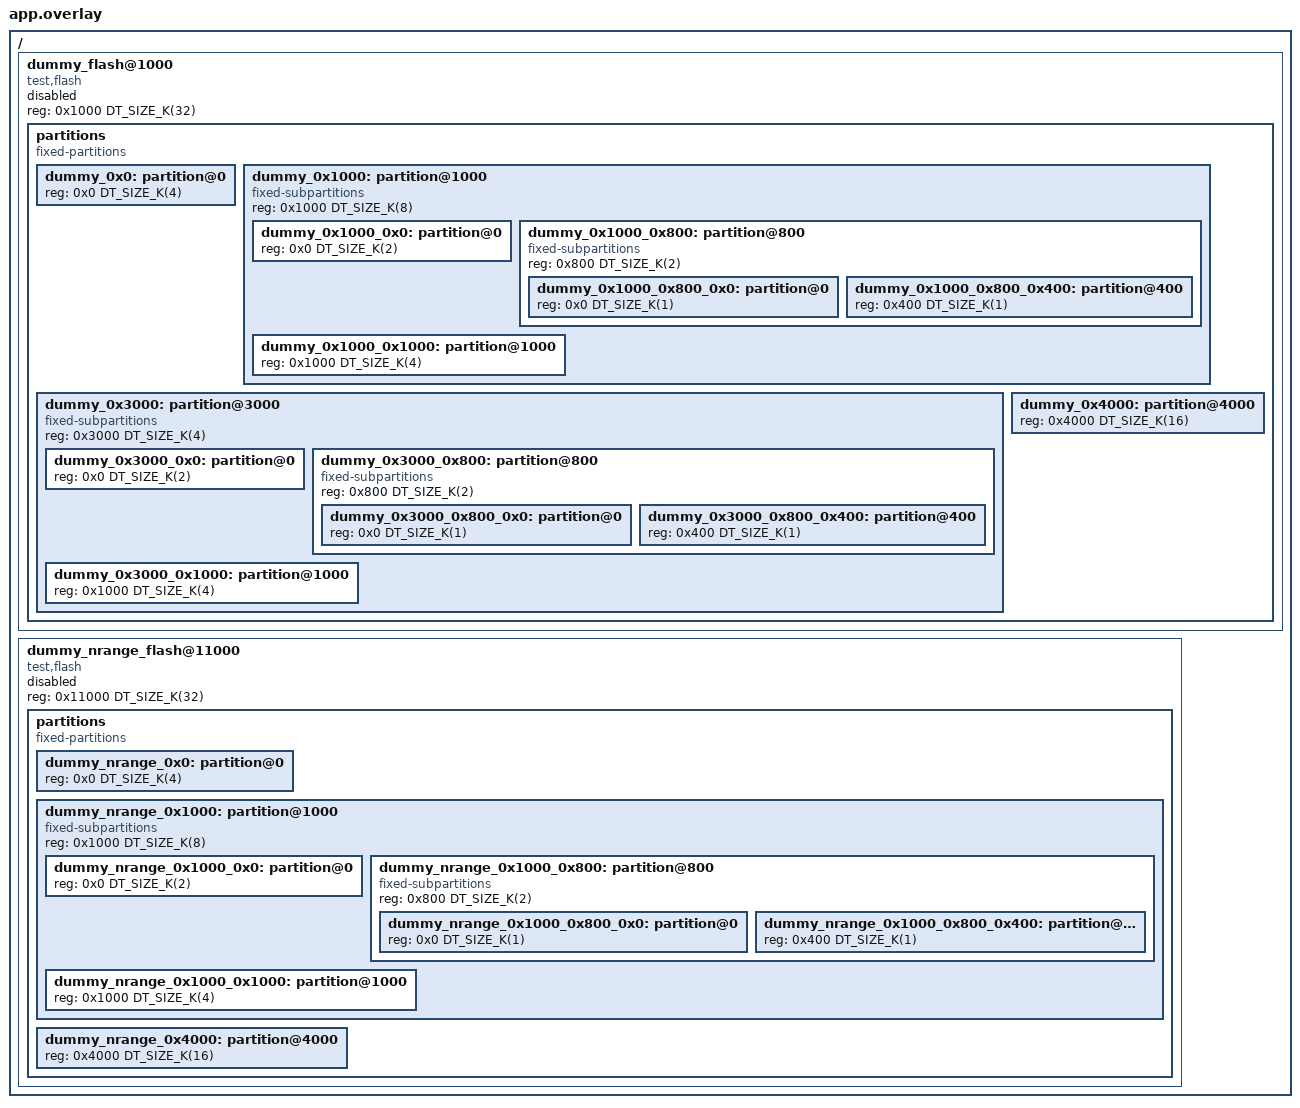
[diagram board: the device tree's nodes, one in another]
/*
 * Copyright (c) 2026 Nordic Semiconductor ASA
 *
 * SPDX-License-Identifier: LicenseRef-Nordic-5-Clause
 */

/ {
	dummy_flash@1000 {
		compatible = "test,flash";
		reg = <0x1000 DT_SIZE_K(32)>;
		ranges = <0x0 0x1000 DT_SIZE_K(32)>;
		status = "disabled";
		#address-cells = <1>;
		#size-cells = <1>;

		partitions {
			compatible = "fixed-partitions";
			ranges;
			#address-cells = <1>;
			#size-cells = <1>;

			dummy_0x0: partition@0 {
				reg = <0x0 DT_SIZE_K(4)>;
			};

			dummy_0x1000: partition@1000 {
				compatible = "fixed-subpartitions";
				reg = <0x1000 DT_SIZE_K(8)>;
				ranges = <0x0 0x1000 DT_SIZE_K(8)>;
				#address-cells = <1>;
				#size-cells = <1>;

				dummy_0x1000_0x0: partition@0 {
					reg = <0x0 DT_SIZE_K(2)>;
				};

				dummy_0x1000_0x800: partition@800 {
					compatible = "fixed-subpartitions";
					reg = <0x800 DT_SIZE_K(2)>;
					ranges = <0x0 0x800 DT_SIZE_K(2)>;
					#address-cells = <1>;
					#size-cells = <1>;

					dummy_0x1000_0x800_0x0: partition@0 {
						reg = <0x0 DT_SIZE_K(1)>;
					};

					dummy_0x1000_0x800_0x400: partition@400 {
						reg = <0x400 DT_SIZE_K(1)>;
					};
				};

				dummy_0x1000_0x1000: partition@1000 {
					reg = <0x1000 DT_SIZE_K(4)>;
				};
			};

			dummy_0x3000: partition@3000 {
				compatible = "fixed-subpartitions";
				reg = <0x3000 DT_SIZE_K(4)>;
				/* Intentionally do not define ranges. */
				#address-cells = <1>;
				#size-cells = <1>;

				dummy_0x3000_0x0: partition@0 {
					reg = <0x0 DT_SIZE_K(2)>;
				};

				dummy_0x3000_0x800: partition@800 {
					compatible = "fixed-subpartitions";
					reg = <0x800 DT_SIZE_K(2)>;
					#address-cells = <1>;
					#size-cells = <1>;

					dummy_0x3000_0x800_0x0: partition@0 {
						reg = <0x0 DT_SIZE_K(1)>;
					};

					dummy_0x3000_0x800_0x400: partition@400 {
						reg = <0x400 DT_SIZE_K(1)>;
					};
				};

				dummy_0x3000_0x1000: partition@1000 {
					reg = <0x1000 DT_SIZE_K(4)>;
				};
			};

			dummy_0x4000: partition@4000 {
				reg = <0x4000 DT_SIZE_K(16)>;
			};
		};
	};

	dummy_nrange_flash@11000 {
		compatible = "test,flash";
		reg = <0x11000 DT_SIZE_K(32)>;
		status = "disabled";

		partitions {
			compatible = "fixed-partitions";
			#address-cells = <1>;
			#size-cells = <1>;

			dummy_nrange_0x0: partition@0 {
				reg = <0x0 DT_SIZE_K(4)>;
			};

			dummy_nrange_0x1000: partition@1000 {
				compatible = "fixed-subpartitions";
				reg = <0x1000 DT_SIZE_K(8)>;
				#address-cells = <1>;
				#size-cells = <1>;

				dummy_nrange_0x1000_0x0: partition@0 {
					reg = <0x0 DT_SIZE_K(2)>;
				};

				dummy_nrange_0x1000_0x800: partition@800 {
					compatible = "fixed-subpartitions";
					reg = <0x800 DT_SIZE_K(2)>;
					#address-cells = <1>;
					#size-cells = <1>;

					dummy_nrange_0x1000_0x800_0x0: partition@0 {
						reg = <0x0 DT_SIZE_K(1)>;
					};

					dummy_nrange_0x1000_0x800_0x400: partition@400 {
						reg = <0x400 DT_SIZE_K(1)>;
					};
				};

				dummy_nrange_0x1000_0x1000: partition@1000 {
					reg = <0x1000 DT_SIZE_K(4)>;
				};
			};

			dummy_nrange_0x4000: partition@4000 {
				reg = <0x4000 DT_SIZE_K(16)>;
			};
		};
	};
};
